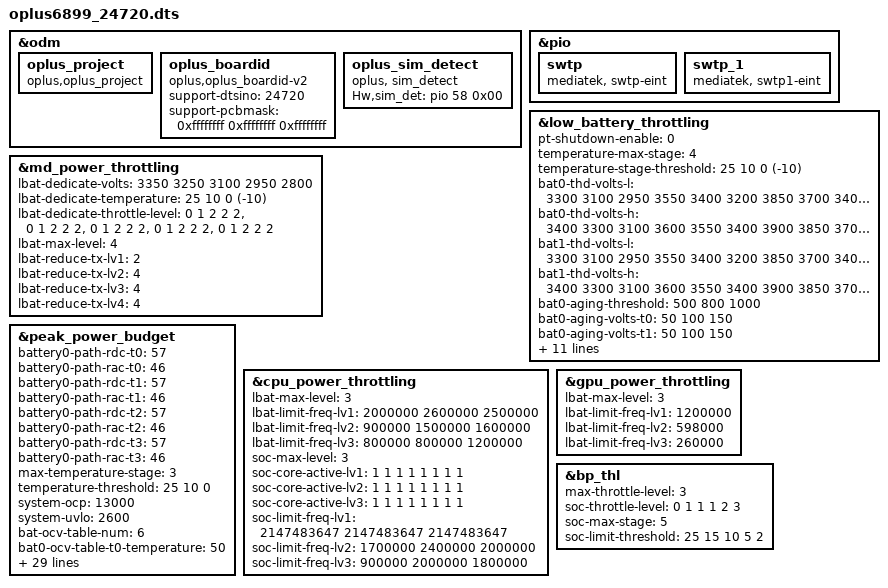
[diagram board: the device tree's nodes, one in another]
// SPDX-License-Identifier: (GPL-2.0 OR MIT)
/*
 * Copyright (C) 2022 MediaTek Inc.
 */
#include "k6899v1_64.dts"

/* #ifdef OPLUS_FEATURE_CHG_BASIC */
/* Add for 24P charge device-tree */
#include "mediatek/oplus_chg/oplus_charge_24720.dtsi"
/* #endif */

/* #ifdef OPLUS_FEATURE_CHG_BASIC */
#include "mediatek/oplus_misc_24720.dtsi"
/* #endif */

/* #ifdef OPLUS_FEATURE_SENSOR */
#include "mediatek/oplus_sensor_24613.dtsi"
/* #endif */

/* #ifdef OPLUS_DISPLAY_FEATURE */
#include "mediatek/oplus-display/mt6899-brz-24720-display-overlay.dtsi"
/* #endif */

&odm {
	/*OPLUS_FEATURE_OEM_OCDT oppo project start */
	oplus_project:oplus_project {
		compatible = "oplus,oplus_project";
    };

    oplus_boardid:oplus_boardid {
        compatible = "oplus,oplus_boardid-v2";
        support-dtsino=<24720>;//only one u32
        /*first one is low 32bit, last one is highest 32bit, must be 32-bit for 4gpios*/
        support-pcbmask=<0xffffffff 0xffffffff 0xffffffff>;
    };
};

&odm {
/* Add for sim detect */
    oplus_sim_detect {
        compatible = "oplus, sim_detect";
        Hw,sim_det = <&pio 58 0x00>;
    };
};

&pio {
	//#ifdef OPLUS_VENDOR_SWTP
	swtp: swtp {
		compatible = "mediatek, swtp-eint";
	};
	 swtp_1: swtp_1 {
        compatible = "mediatek, swtp1-eint";
    };
	//#endif  /*OPLUS_VENDOR_SWTP*/
};

&low_battery_throttling {
	pt-shutdown-enable = <0>;
	temperature-max-stage = <4>;
	temperature-stage-threshold = <25 10 0 (-10)>;
	bat0-thd-volts-l = <
			3300 3100 2950
			3550 3400 3200
			3850 3700 3400
			4050 3900 3500
			4250 4040 3580>;
	bat0-thd-volts-h = <
			3400 3300 3100
			3600 3550 3400
			3900 3850 3700
			4100 4050 3900
			4300 4250 4040>;
	bat1-thd-volts-l = <
			3300 3100 2950
			3550 3400 3200
			3850 3700 3400
			4050 3900 3500
			4250 4040 3580>;
	bat1-thd-volts-h = <
			3400 3300 3100
			3600 3550 3400
			3900 3850 3700
			4100 4050 3900
			4300 4250 4040>;

		bat0-aging-threshold = <500 800 1000>;
		bat0-aging-volts-t0 =  <50 100 150>;
		bat0-aging-volts-t1 =  <50 100 150>;
		bat0-aging-volts-t2 =  <50 100 150>;
		bat0-aging-volts-t3 =  <50 100 150>;
		bat0-aging-volts-t4 =  <50 100 150>;
		bat1-aging-threshold = <500 800 1000>;
		bat1-aging-volts-t0 =  <0 0>;
		bat1-aging-volts-t1 =  <0 0>;
		bat1-aging-volts-t2 =  <0 0>;
		bat1-aging-volts-t3 =  <0 0>;
		bat1-aging-volts-t4 =  <0 0>;
		throttle-level =  <0 1 2 3>,
				  <0 1 2 3>,
				  <0 1 2 3>,
				  <0 2 3 3>,
				  <0 2 3 3>;
};

&md_power_throttling{
		lbat-dedicate-volts = <3350 3250 3100 2950 2800>;
		lbat-dedicate-temperature = <25 10 0 (-10)>;
		lbat-dedicate-throttle-level =  < 0 1 2 2 2>,
						< 0 1 2 2 2>,
						< 0 1 2 2 2>,
						< 0 1 2 2 2>,
						< 0 1 2 2 2>;

		lbat-max-level = <4>;
		lbat-reduce-tx-lv1 = <2>;
		lbat-reduce-tx-lv2 = <4>;
		lbat-reduce-tx-lv3 = <4>;
		lbat-reduce-tx-lv4 = <4>;
};

&peak_power_budget {
	battery0-path-rdc-t0 = <57>;
	battery0-path-rac-t0 = <46>;
	battery0-path-rdc-t1 = <57>;
	battery0-path-rac-t1 = <46>;
	battery0-path-rdc-t2 = <57>;
	battery0-path-rac-t2 = <46>;
	battery0-path-rdc-t3 = <57>;
	battery0-path-rac-t3 = <46>;
	max-temperature-stage = <3>;
	temperature-threshold = <25 10 0>;
	system-ocp = <13000>;
	system-uvlo = <2600>;

	bat-ocv-table-num = <6>;

	bat0-ocv-table-t0-temperature = <50>;
	bat0-ocv-table-t0-qmax = <6796>;
	bat0-ocv-table-t0-size = <100>;
	bat0-ocv-table-t0 = <
		0       44580   0
		352     44453   0
		703     44341   0
		1055    44242   0
		1406    44146   0
		1758    44053   0
		2109    43961   0
		2461    43863   0
		2812    43768   0
		3164    43670   0
		3515    43567   0
		3867    43463   0
		4218    43355   0
		4570    43243   0
		4921    43132   0
		5273    43019   0
		5624    42901   0
		5976    42778   0
		6327    42661   0
		6679    42539   0
		7030    42417   0
		7382    42294   0
		7733    42171   0
		8085    42049   0
		8436    41926   0
		8788    41800   0
		9139    41673   0
		9491    41538   0
		9842    41391   0
		10194   41211   0
		10545   41016   0
		10897   40844   0
		11248   40707   0
		11600   40587   0
		11952   40473   0
		12303   40363   0
		12655   40254   0
		13006   40150   0
		13358   40050   0
		13709   39952   0
		14061   39855   0
		14412   39763   0
		14764   39667   0
		15115   39579   0
		15467   39492   0
		15818   39403   0
		16170   39307   0
		16521   39189   0
		16873   39044   0
		17224   38902   0
		17576   38779   0
		17927   38664   0
		18279   38551   0
		18630   38445   0
		18982   38343   0
		19333   38236   0
		19685   38116   0
		20036   37990   0
		20388   37879   0
		20739   37761   0
		21091   37646   0
		21442   37551   0
		21794   37476   0
		22145   37410   0
		22497   37343   0
		22848   37264   0
		23200   37155   0
		23552   37049   0
		23903   36938   0
		24255   36820   0
		24606   36697   0
		24958   36570   0
		25309   36437   0
		25661   36295   0
		26012   36143   0
		26364   35984   0
		26715   35821   0
		27067   35658   0
		27418   35496   0
		27770   35339   0
		28121   35186   0
		28473   35031   0
		28824   34878   0
		29176   34714   0
		29527   34541   0
		29879   34360   0
		30230   34163   0
		30582   33947   0
		30933   33716   0
		31285   33473   0
		31636   33220   0
		31988   32973   0
		32339   32730   0
		32691   32492   0
		33042   32245   0
		33394   31969   0
		33745   31627   0
		34097   31162   0
		34448   30626   0
		34800   30626   0>;

	bat0-ocv-table-t1-temperature = <25>;
	bat0-ocv-table-t1-qmax = <6848>;
	bat0-ocv-table-t1-size = <100>;
	bat0-ocv-table-t1 = <
		0       89087   0
		347     88828   0
		695     88611   0
		1042    88412   0
		1390    88224   0
		1737    88036   0
		2085    87844   0
		2432    87654   0
		2780    87456   0
		3127    87256   0
		3475    87048   0
		3822    86838   0
		4170    86620   0
		4517    86394   0
		4865    86167   0
		5212    85935   0
		5560    85704   0
		5907    85463   0
		6255    85216   0
		6602    84971   0
		6949    84726   0
		7297    84479   0
		7644    84231   0
		7992    83984   0
		8339    83741   0
		8687    83490   0
		9034    83244   0
		9382    82990   0
		9729    82714   0
		10077   82399   0
		10424   82014   0
		10772   81605   0
		11119   81285   0
		11467   81018   0
		11814   80778   0
		12162   80551   0
		12509   80338   0
		12857   80138   0
		13204   79933   0
		13552   79739   0
		13899   79550   0
		14246   79369   0
		14594   79191   0
		14941   79016   0
		15289   78846   0
		15636   78684   0
		15984   78517   0
		16331   78355   0
		16679   78172   0
		17026   77966   0
		17374   77745   0
		17721   77516   0
		18069   77286   0
		18416   77061   0
		18764   76856   0
		19111   76656   0
		19459   76433   0
		19806   76192   0
		20154   75954   0
		20501   75724   0
		20848   75485   0
		21196   75238   0
		21543   75065   0
		21891   74924   0
		22238   74800   0
		22586   74670   0
		22933   74493   0
		23281   74253   0
		23628   74007   0
		23976   73770   0
		24323   73523   0
		24671   73271   0
		25018   73008   0
		25366   72731   0
		25713   72438   0
		26061   72128   0
		26408   71804   0
		26756   71476   0
		27103   71143   0
		27451   70821   0
		27798   70500   0
		28145   70179   0
		28493   69860   0
		28840   69534   0
		29188   69189   0
		29535   68819   0
		29883   68416   0
		30230   67986   0
		30578   67519   0
		30925   67016   0
		31273   66491   0
		31620   65981   0
		31968   65496   0
		32315   65011   0
		32663   64518   0
		33010   63971   0
		33358   63279   0
		33705   62318   0
		34053   60954   0
		34400   59095   0>;

	bat0-ocv-table-t2-temperature = <10>;
	bat0-ocv-table-t2-qmax = <6400>;
	bat0-ocv-table-t2-size = <100>;
	bat0-ocv-table-t2 = <
		0       44525   0
		352     44372   0
		703     44257   0
		1055    44160   0
		1406    44070   0
		1758    43981   0
		2109    43890   0
		2461    43802   0
		2812    43709   0
		3164    43611   0
		3515    43508   0
		3867    43404   0
		4218    43301   0
		4570    43194   0
		4921    43084   0
		5273    42969   0
		5624    42855   0
		5976    42734   0
		6327    42610   0
		6679    42489   0
		7030    42365   0
		7382    42240   0
		7733    42115   0
		8085    41990   0
		8436    41863   0
		8788    41733   0
		9139    41602   0
		9491    41466   0
		9842    41316   0
		10194   41140   0
		10545   40949   0
		10897   40766   0
		11248   40605   0
		11600   40457   0
		11952   40331   0
		12303   40220   0
		12655   40111   0
		13006   40006   0
		13358   39903   0
		13709   39800   0
		14061   39703   0
		14412   39611   0
		14764   39518   0
		15115   39425   0
		15467   39337   0
		15818   39253   0
		16170   39169   0
		16521   39082   0
		16873   38995   0
		17224   38912   0
		17576   38815   0
		17927   38707   0
		18279   38589   0
		18630   38469   0
		18982   38360   0
		19333   38256   0
		19685   38139   0
		20036   38013   0
		20388   37883   0
		20739   37762   0
		21091   37638   0
		21442   37520   0
		21794   37426   0
		22145   37357   0
		22497   37294   0
		22848   37220   0
		23200   37127   0
		23552   36980   0
		23903   36847   0
		24255   36721   0
		24606   36595   0
		24958   36467   0
		25309   36335   0
		25661   36197   0
		26012   36050   0
		26364   35891   0
		26715   35724   0
		27067   35555   0
		27418   35386   0
		27770   35217   0
		28121   35050   0
		28473   34886   0
		28824   34722   0
		29176   34548   0
		29527   34368   0
		29879   34176   0
		30230   33962   0
		30582   33730   0
		30933   33484   0
		31285   33225   0
		31636   32959   0
		31988   32703   0
		32339   32457   0
		32691   32208   0
		33042   31946   0
		33394   31826   0
		33745   31826   0
		34097   31826   0
		34448   31826   0
		34800   31826   0>;

	bat0-ocv-table-t3-temperature = <0>;
	bat0-ocv-table-t3-qmax = <6008>;
	bat0-ocv-table-t3-size = <100>;
	bat0-ocv-table-t3 = <
		0       44580   0
		352     44417   0
		703     44300   0
		1055    44199   0
		1406    44104   0
		1758    44014   0
		2109    43925   0
		2461    43833   0
		2812    43740   0
		3164    43648   0
		3515    43550   0
		3867    43452   0
		4218    43351   0
		4570    43244   0
		4921    43135   0
		5273    43026   0
		5624    42917   0
		5976    42796   0
		6327    42677   0
		6679    42557   0
		7030    42434   0
		7382    42305   0
		7733    42177   0
		8085    42049   0
		8436    41912   0
		8788    41770   0
		9139    41613   0
		9491    41451   0
		9842    41279   0
		10194   41105   0
		10545   40938   0
		10897   40784   0
		11248   40644   0
		11600   40513   0
		11952   40393   0
		12303   40278   0
		12655   40167   0
		13006   40061   0
		13358   39958   0
		13709   39855   0
		14061   39752   0
		14412   39654   0
		14764   39562   0
		15115   39468   0
		15467   39376   0
		15818   39284   0
		16170   39197   0
		16521   39111   0
		16873   39017   0
		17224   38920   0
		17576   38826   0
		17927   38719   0
		18279   38605   0
		18630   38491   0
		18982   38374   0
		19333   38250   0
		19685   38118   0
		20036   37983   0
		20388   37857   0
		20739   37727   0
		21091   37609   0
		21442   37514   0
		21794   37436   0
		22145   37365   0
		22497   37289   0
		22848   37192   0
		23200   37034   0
		23552   36871   0
		23903   36736   0
		24255   36613   0
		24606   36490   0
		24958   36362   0
		25309   36228   0
		25661   36085   0
		26012   35932   0
		26364   35773   0
		26715   35606   0
		27067   35433   0
		27418   35255   0
		27770   35072   0
		28121   34891   0
		28473   34716   0
		28824   34535   0
		29176   34344   0
		29527   34149   0
		29879   33935   0
		30230   33706   0
		30582   33466   0
		30933   33217   0
		31285   33023   0
		31636   33023   0
		31988   33023   0
		32339   33023   0
		32691   33023   0
		33042   33023   0
		33394   33023   0
		33745   33023   0
		34097   33023   0
		34448   33023   0
		34800   33023   0>;

	bat-ocv-table-t4-temperature = <(-10)>;
	bat-ocv-table-t4-qmax = <5554>;
	bat-ocv-table-t4-size = <100>;
	bat-ocv-table-t4 = <
		0       44587   0
		352     44396   0
		703     44247   0
		1055    44121   0
		1406    44008   0
		1758    43897   0
		2109    43786   0
		2461    43681   0
		2812    43572   0
		3164    43463   0
		3515    43359   0
		3867    43247   0
		4218    43133   0
		4570    43018   0
		4921    42904   0
		5273    42787   0
		5624    42663   0
		5976    42542   0
		6327    42418   0
		6679    42292   0
		7030    42167   0
		7382    42039   0
		7733    41906   0
		8085    41767   0
		8436    41619   0
		8788    41467   0
		9139    41314   0
		9491    41157   0
		9842    41003   0
		10194   40848   0
		10545   40694   0
		10897   40549   0
		11248   40415   0
		11600   40290   0
		11952   40170   0
		12303   40055   0
		12655   39944   0
		13006   39835   0
		13358   39734   0
		13709   39638   0
		14061   39536   0
		14412   39443   0
		14764   39351   0
		15115   39263   0
		15467   39176   0
		15818   39085   0
		16170   38995   0
		16521   38910   0
		16873   38827   0
		17224   38740   0
		17576   38646   0
		17927   38554   0
		18279   38457   0
		18630   38352   0
		18982   38243   0
		19333   38130   0
		19685   38009   0
		20036   37883   0
		20388   37758   0
		20739   37633   0
		21091   37507   0
		21442   37408   0
		21794   37330   0
		22145   37262   0
		22497   37193   0
		22848   37109   0
		23200   36979   0
		23552   36761   0
		23903   36580   0
		24255   36437   0
		24606   36303   0
		24958   36167   0
		25309   36024   0
		25661   35864   0
		26012   35689   0
		26364   35510   0
		26715   35315   0
		27067   35118   0
		27418   34916   0
		27770   34709   0
		28121   34500   0
		28473   34286   0
		28824   34083   0
		29176   34083   0
		29527   34083   0
		29879   34083   0
		30230   34083   0
		30582   34083   0
		30933   34083   0
		31285   34083   0
		31636   34083   0
		31988   34083   0
		32339   34083   0
		32691   34083   0
		33042   34083   0
		33394   34083   0
		33745   34083   0
		34097   34083   0
		34448   34083   0
		34800   34083   0>;

	bat-ocv-table-t5-temperature = <(-20)>;
	bat-ocv-table-t5-qmax = <4906>;
	bat-ocv-table-t5-size = <100>;
	bat-ocv-table-t5 = <
		0       44680   0
		352     44391   0
		703     44178   0
		1055    43999   0
		1406    43837   0
		1758    43681   0
		2109    43530   0
		2461    43384   0
		2812    43242   0
		3164    43106   0
		3515    42970   0
		3867    42838   0
		4218    42707   0
		4570    42584   0
		4921    42458   0
		5273    42315   0
		5624    42184   0
		5976    42047   0
		6327    41922   0
		6679    41788   0
		7030    41655   0
		7382    41522   0
		7733    41387   0
		8085    41254   0
		8436    41113   0
		8788    40977   0
		9139    40840   0
		9491    40709   0
		9842    40574   0
		10194   40441   0
		10545   40315   0
		10897   40193   0
		11248   40069   0
		11600   39955   0
		11952   39841   0
		12303   39731   0
		12655   39626   0
		13006   39528   0
		13358   39433   0
		13709   39335   0
		14061   39240   0
		14412   39158   0
		14764   39066   0
		15115   38978   0
		15467   38895   0
		15818   38809   0
		16170   38722   0
		16521   38637   0
		16873   38555   0
		17224   38473   0
		17576   38392   0
		17927   38310   0
		18279   38228   0
		18630   38140   0
		18982   38050   0
		19333   37961   0
		19685   37866   0
		20036   37769   0
		20388   37670   0
		20739   37583   0
		21091   37491   0
		21442   37406   0
		21794   37330   0
		22145   37260   0
		22497   37188   0
		22848   37112   0
		23200   37003   0
		23552   36834   0
		23903   36623   0
		24255   36417   0
		24606   36231   0
		24958   36059   0
		25309   35891   0
		25661   35721   0
		26012   35547   0
		26364   35361   0
		26715   35342   0
		27067   35342   0
		27418   35342   0
		27770   35342   0
		28121   35342   0
		28473   35342   0
		28824   35342   0
		29176   35342   0
		29527   35342   0
		29879   35342   0
		30230   35342   0
		30582   35342   0
		30933   35342   0
		31285   35342   0
		31636   35342   0
		31988   35342   0
		32339   35342   0
		32691   35342   0
		33042   35342   0
		33394   35342   0
		33745   35342   0
		34097   35342   0
		34448   35342   0
		34800   35342   0>;
};

&cpu_power_throttling {
    lbat-max-level = <3>;
    lbat-limit-freq-lv1 = < 2000000 2600000 2500000>;
    lbat-limit-freq-lv2 = < 900000 1500000 1600000>;
    lbat-limit-freq-lv3 = < 800000 800000 1200000>;

	soc-max-level = <3>;
	soc-core-active-lv1 = < 1 1 1 1 1 1 1 1 >;
	soc-core-active-lv2 = < 1 1 1 1 1 1 1 1 >;
	soc-core-active-lv3 = < 1 1 1 1 1 1 1 1 >;

	soc-limit-freq-lv1 = < 2147483647  2147483647 2147483647 >;
	soc-limit-freq-lv2 = < 1700000 2400000 2000000>;
	soc-limit-freq-lv3 = < 900000 2000000 1800000>;
};

&gpu_power_throttling {
    lbat-max-level = <3>;
    lbat-limit-freq-lv1 = <1200000>;
    lbat-limit-freq-lv2 = <598000>;
    lbat-limit-freq-lv3 = <260000>;
};

&bp_thl {
	max-throttle-level = <3>;   //+lv3
	soc-throttle-level =
		<0 1 1 1 2 3>;
	soc-max-stage = <5>;
	soc-limit-threshold = <25 15 10 5 2>;
};

#include "mediatek/cust_mt6899_brzb_camera_v4l2.dtsi"
#include "mediatek/oplus6899_common.dtsi"
#include <oplus6899_24720/cust.dtsi>
#include "cust_mt6899_brz_audio.dtsi"
#include "oplus_tp_24720.dtsi"
/* Add for brz(24613) fingerprint device-tree */
/* #ifdef CONFIG_UFF_FINGERPRINT */
#include "oplus_uff_24613.dtsi"
//NFC dtsi
#include "mediatek/nfc/mt6899_24720_pn560.dtsi"
//thermal dtsi
#include "mediatek/cust_mt6899_brz_thermal.dtsi"
/*End of this file, DO NOT ADD ANYTHING HERE*/
